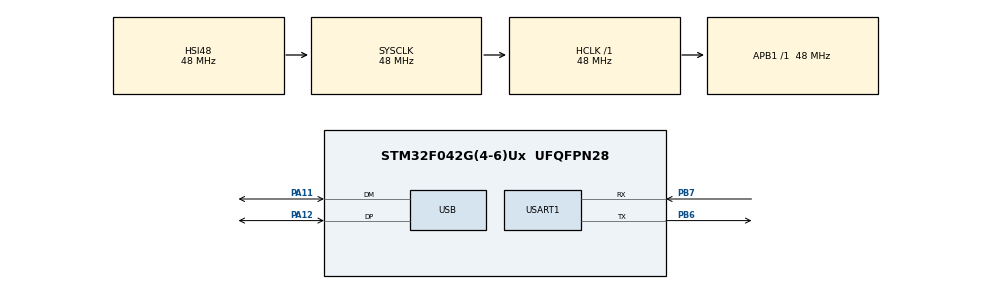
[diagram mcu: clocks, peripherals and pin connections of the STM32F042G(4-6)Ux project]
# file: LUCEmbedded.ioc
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Mcu.Family=STM32F0
Mcu.Name=STM32F042G(4-6)Ux
Mcu.Package=UFQFPN28
NVIC.USART1_IRQn=true\:0\:0\:false\:false\:true\:true\:true\:true
NVIC.USB_IRQn=true\:1\:0\:false\:false\:true\:false\:true\:true
PA11.Mode=Device
PA11.Signal=USB_DM
PA12.Mode=Device
PA12.Signal=USB_DP
PA13.Mode=Serial_Wire
PA13.Signal=SYS_SWDIO
PA14.Mode=Serial_Wire
PA14.Signal=SYS_SWCLK
PB6.Mode=LIN
PB6.Signal=USART1_TX
PB7.Mode=LIN
PB7.Signal=USART1_RX
ProjectManager.HeapSize=0x200
ProjectManager.StackSize=0x400
ProjectManager.TargetToolchain=STM32CubeIDE
RCC.AHBFreq_Value=48000000
RCC.APB1Freq_Value=48000000
RCC.APB1TimFreq_Value=48000000
RCC.HCLKFreq_Value=48000000
RCC.SYSCLKFreq_VALUE=48000000
RCC.SYSCLKSource=RCC_SYSCLKSOURCE_HSI48
USART1.AutoBaudRateEnableParam=UART_ADVFEATURE_AUTOBAUDRATE_DISABLE
USART1.BaudRate=lin_baund_rate
USART1.BreakDetectLength=UART_LINBREAKDETECTLENGTH_11B
USART1.VirtualMode-LIN=VM_LIN
USART1.WordLength=WORDLENGTH_8B
USB_DEVICE.APP_RX_DATA_SIZE=64
USB_DEVICE.APP_TX_DATA_SIZE=64
USB_DEVICE.CLASS_NAME_FS=CDC
USB_DEVICE.MANUFACTURER_STRING=uCAN
USB_DEVICE.PRODUCT_STRING_CDC_FS=LinUSBConverter
USB_DEVICE.VirtualMode=Cdc
USB_DEVICE.VirtualModeFS=Cdc_FS
VP_SYS_VS_PINREMAP.Mode=PINREMAP
VP_USB_DEVICE_VS_USB_DEVICE_CDC_FS.Mode=CDC_FS
board=LUCEmbedded

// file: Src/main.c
/* USER CODE BEGIN Header */
/**
  ******************************************************************************
  * @file           : main.c
  * @brief          : Main program body
  ******************************************************************************
  * @attention
  *
  * Copyright (c) 2026 STMicroelectronics.
  * All rights reserved.
  *
  * This software is licensed under terms that can be found in the LICENSE file
  * in the root directory of this software component.
  * If no LICENSE file comes with this software, it is provided AS-IS.
  *
  ******************************************************************************
  */
/* USER CODE END Header */
#include "main.h"
#include "usart.h"
#include "usb_device.h"
#include "gpio.h"

/* USER CODE BEGIN Includes */
#include "luc_lin.h"
#include "luc_proto.h"
#include "luc_port_stm32.h"

/* USER CODE END Includes */

void SystemClock_Config(void);

/* USER CODE BEGIN 0 */
uint32_t lin_baund_rate = 19200;   /* von MX_USART1_UART_Init verwendet */
/* USER CODE END 0 */

int main(void)
{

  /* MCU Configuration--------------------------------------------------------*/

  /* Reset of all peripherals, Initializes the Flash interface and the Systick. */
  HAL_Init();

  /* Configure the system clock */
  SystemClock_Config();

  /* Initialize all configured peripherals */
  MX_GPIO_Init();
  MX_USART1_UART_Init();
  MX_USB_DEVICE_Init();
  /* USER CODE BEGIN 2 */
  luc_lin_init();      /* stellt auch die Baudrate ein */
  luc_proto_init();
  luc_port_init();     /* USART1-Interrupts (Break, RXNE) */
  /* USER CODE END 2 */

  /* Infinite loop */
  /* USER CODE BEGIN WHILE */
  while (1)
  {
	  luc_lin_poll();        /* Schedule, Diagnose, Timeouts             */
	  luc_proto_poll();      /* Befehle ausfuehren, Ereignisse ausgeben  */
	  luc_port_usb_pump();   /* ein USB-Paket aus dem Sendering absenden */
    /* USER CODE END WHILE */

  }
}

void SystemClock_Config(void)
{
  RCC_OscInitTypeDef RCC_OscInitStruct = {0};
  RCC_ClkInitTypeDef RCC_ClkInitStruct = {0};
  RCC_PeriphCLKInitTypeDef PeriphClkInit = {0};

  /** Initializes the RCC Oscillators according to the specified parameters
  * in the RCC_OscInitTypeDef structure.
  */
  RCC_OscInitStruct.OscillatorType = RCC_OSCILLATORTYPE_HSI48;
  RCC_OscInitStruct.HSI48State = RCC_HSI48_ON;
  RCC_OscInitStruct.PLL.PLLState = RCC_PLL_NONE;
  if (HAL_RCC_OscConfig(&RCC_OscInitStruct) != HAL_OK)
  {
    Error_Handler();
  }

  /** Initializes the CPU, AHB and APB buses clocks
  */
  RCC_ClkInitStruct.ClockType = RCC_CLOCKTYPE_HCLK|RCC_CLOCKTYPE_SYSCLK
                              |RCC_CLOCKTYPE_PCLK1;
  RCC_ClkInitStruct.SYSCLKSource = RCC_SYSCLKSOURCE_HSI48;
  RCC_ClkInitStruct.AHBCLKDivider = RCC_SYSCLK_DIV1;
  RCC_ClkInitStruct.APB1CLKDivider = RCC_HCLK_DIV1;

  if (HAL_RCC_ClockConfig(&RCC_ClkInitStruct, FLASH_LATENCY_1) != HAL_OK)
  {
    Error_Handler();
  }
  PeriphClkInit.PeriphClockSelection = RCC_PERIPHCLK_USB|RCC_PERIPHCLK_USART1;
  PeriphClkInit.Usart1ClockSelection = RCC_USART1CLKSOURCE_PCLK1;
  PeriphClkInit.UsbClockSelection = RCC_USBCLKSOURCE_HSI48;

  if (HAL_RCCEx_PeriphCLKConfig(&PeriphClkInit) != HAL_OK)
  {
    Error_Handler();
  }
}

void Error_Handler(void)
{
  __disable_irq();
  while (1)
  {
  }
}
